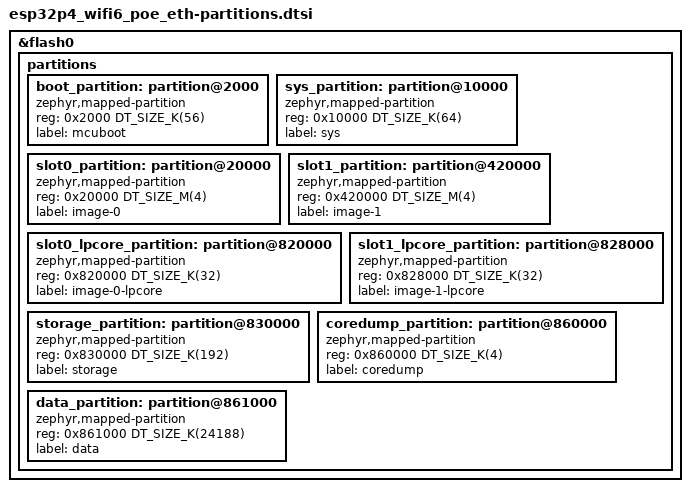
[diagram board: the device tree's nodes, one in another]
/*
 * Copyright (c) 2026 Richard Osterloh <richard.osterloh@gmail.com>
 * SPDX-License-Identifier: Apache-2.0
 *
 * The 16M default table's layout with 4 MB image slots, and the rest of the
 * 32 MB flash as a data partition. Shared by the HP and LP core so their
 * offsets agree.
 *
 * MCUboot sizes its sector table from the slot size
 * (CONFIG_BOOT_MAX_IMG_SECTORS_AUTO), one entry per 4 KB sector. The default
 * tables' 7936 KB (16M) and 16128 KB (32M) slots make that ~31 KB and ~64 KB of
 * .bss, which overflows the bootloader's dram_seg. 4 MB slots cost 16 KB.
 * Capping BOOT_MAX_IMG_SECTORS instead fails at boot, not build.
 */

&flash0 {
	partitions {
		ranges;
		#address-cells = <1>;
		#size-cells = <1>;

		boot_partition: partition@2000 {
			compatible = "zephyr,mapped-partition";
			reg = <0x2000 DT_SIZE_K(56)>;
			label = "mcuboot";
		};

		sys_partition: partition@10000 {
			compatible = "zephyr,mapped-partition";
			reg = <0x10000 DT_SIZE_K(64)>;
			label = "sys";
		};

		slot0_partition: partition@20000 {
			compatible = "zephyr,mapped-partition";
			reg = <0x20000 DT_SIZE_M(4)>;
			label = "image-0";
		};

		slot1_partition: partition@420000 {
			compatible = "zephyr,mapped-partition";
			reg = <0x420000 DT_SIZE_M(4)>;
			label = "image-1";
		};

		slot0_lpcore_partition: partition@820000 {
			compatible = "zephyr,mapped-partition";
			reg = <0x820000 DT_SIZE_K(32)>;
			label = "image-0-lpcore";
		};

		slot1_lpcore_partition: partition@828000 {
			compatible = "zephyr,mapped-partition";
			reg = <0x828000 DT_SIZE_K(32)>;
			label = "image-1-lpcore";
		};

		storage_partition: partition@830000 {
			compatible = "zephyr,mapped-partition";
			reg = <0x830000 DT_SIZE_K(192)>;
			label = "storage";
		};

		coredump_partition: partition@860000 {
			compatible = "zephyr,mapped-partition";
			reg = <0x860000 DT_SIZE_K(4)>;
			label = "coredump";
		};

		/* The rest of the 32 MB flash, for an application file system. */
		data_partition: partition@861000 {
			compatible = "zephyr,mapped-partition";
			reg = <0x861000 DT_SIZE_K(24188)>;
			label = "data";
		};
	};
};
